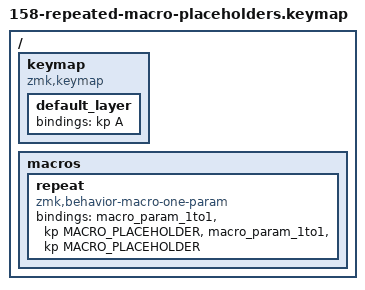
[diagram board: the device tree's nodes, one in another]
/* Issue #158: each repeated macro parameter directive keeps its placeholder. */
/ {
    keymap {
        compatible = "zmk,keymap";
        default_layer { bindings = <&kp A>; };
    };
    macros {
        repeat: repeat {
            compatible = "zmk,behavior-macro-one-param";
            #binding-cells = <1>;
            bindings = <&macro_param_1to1 &kp MACRO_PLACEHOLDER &macro_param_1to1 &kp MACRO_PLACEHOLDER>;
        };
    };

};
